# ATmega1284RFR2 device description
Architecture: AVR8; Family: megaAVR
Registers are 8-bit, access not given, no defined reset value unless marked. A register's access mark holds for its fields unless they carry their own. Offsets are from the block's base; [hi:lo] are bit positions.

## SYMCNT — MAC Symbol Counter
Instances: SYMCNT 0x00
0xD7 SCRSTRLL — Symbol Counter Received Frame Timestamp Register LL-Byte
0xD8 SCRSTRLH — Symbol Counter Received Frame Timestamp Register LH-Byte
0xD9 SCRSTRHL — Symbol Counter Received Frame Timestamp Register HL-Byte
0xDA SCRSTRHH — Symbol Counter Received Frame Timestamp Register HH-Byte
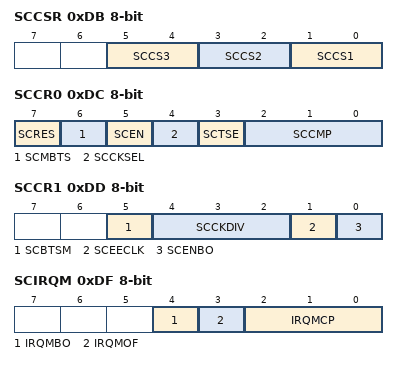
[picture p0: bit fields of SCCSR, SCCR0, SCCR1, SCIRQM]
0xDB SCCSR — Symbol Counter Compare Source Register
  [5:4] SCCS3 — Symbol Counter Compare Source select register for Compare Unit 3
    0=Compare Unit 3 Relative Compare Source = Beacon Timestamp Register; 1=Compare Unit 3 Relative Compare Source = Transmit Frame Timestamp Register; 2=Compare Unit 3 Relative Compare Source = Received Frame Timestamp Register
  [3:2] SCCS2 — Symbol Counter Compare Source select register for Compare Unit 2
    0=Compare Unit 2 Relative Compare Source = Beacon Timestamp Register; 1=Compare Unit 2 Relative Compare Source = Transmit Frame Timestamp Register; 2=Compare Unit 2 Relative Compare Source = Received Frame Timestamp Register
  [1:0] SCCS1 — Symbol Counter Compare Source select register for Compare Units
    0=Compare Unit 1 Relative Compare Source = Beacon Timestamp Register; 1=Compare Unit 1 Relative Compare Source = Transmit Frame Timestamp Register; 2=Compare Unit 1 Relative Compare Source = Received Frame Timestamp Register
0xDC SCCR0 — Symbol Counter Control Register 0
  [7] SCRES — Symbol Counter Synchronization
  [6] SCMBTS — Manual Beacon Timestamp
  [5] SCEN — Symbol Counter enable
  [4] SCCKSEL — Symbol Counter Clock Source select
  [3] SCTSE — Symbol Counter Automatic Timestamping enable
  [2:0] SCCMP (bit 1 of the value upward) — Symbol Counter Compare Unit 3 Mode select
0xDD SCCR1 — Symbol Counter Control Register 1
  [5] SCBTSM — Symbol Counter Beacon Timestamp Mask Register
  [4:2] SCCKDIV — Clock divider for synchronous clock source (16MHz Transceiver Clock)
    0=Transceiver Clock divided by 256, (62.5kHz); 1=Transceiver Clock divided by 128, (125kHz); 2=Transceiver Clock divided by 64, (250kHz); 3=Transceiver Clock divided by 32, (500kHz); 4=Transceiver Clock divided by 16, (1MHz); 5=Transceiver Clock divided by 8, (2MHz); 6=Transceiver Clock divided by 4, (4MHz)
  [1] SCEECLK — Enable External Clock Source on PG2
  [0] SCENBO — Backoff Slot Counter enable
0xDE SCSR — Symbol Counter Status Register
  [0] SCBSY — Symbol Counter busy
0xDF SCIRQM — Symbol Counter Interrupt Mask Register
  [4] IRQMBO — Backoff Slot Counter IRQ enable
  [3] IRQMOF — Symbol Counter Overflow IRQ enable
  [2:0] IRQMCP (bit 1 of the value upward) — Symbol Counter Compare Match 3 IRQ enable
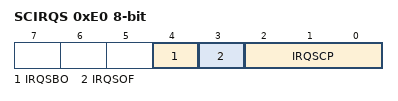
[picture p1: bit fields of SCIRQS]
0xE0 SCIRQS — Symbol Counter Interrupt Status Register
  [4] IRQSBO — Backoff Slot Counter IRQ
  [3] IRQSOF — Symbol Counter Overflow IRQ
  [2:0] IRQSCP (bit 1 of the value upward) — Compare Unit 3 Compare Match IRQ
0xE1 SCCNTLL — Symbol Counter Register LL-Byte
0xE2 SCCNTLH — Symbol Counter Register LH-Byte
0xE3 SCCNTHL — Symbol Counter Register HL-Byte
0xE4 SCCNTHH — Symbol Counter Register HH-Byte
0xE5 SCBTSRLL — Symbol Counter Beacon Timestamp Register LL-Byte
0xE6 SCBTSRLH — Symbol Counter Beacon Timestamp Register LH-Byte
0xE7 SCBTSRHL — Symbol Counter Beacon Timestamp Register HL-Byte
0xE8 SCBTSRHH — Symbol Counter Beacon Timestamp Register HH-Byte
0xE9 SCTSRLL — Symbol Counter Frame Timestamp Register LL-Byte
0xEA SCTSRLH — Symbol Counter Frame Timestamp Register LH-Byte
0xEB SCTSRHL — Symbol Counter Frame Timestamp Register HL-Byte
0xEC SCTSRHH — Symbol Counter Frame Timestamp Register HH-Byte
0xED SCOCR3LL — Symbol Counter Output Compare Register 3 LL-Byte
0xEE SCOCR3LH — Symbol Counter Output Compare Register 3 LH-Byte
0xEF SCOCR3HL — Symbol Counter Output Compare Register 3 HL-Byte
0xF0 SCOCR3HH — Symbol Counter Output Compare Register 3 HH-Byte
0xF1 SCOCR2LL — Symbol Counter Output Compare Register 2 LL-Byte
0xF2 SCOCR2LH — Symbol Counter Output Compare Register 2 LH-Byte
0xF3 SCOCR2HL — Symbol Counter Output Compare Register 2 HL-Byte
0xF4 SCOCR2HH — Symbol Counter Output Compare Register 2 HH-Byte
0xF5 SCOCR1LL — Symbol Counter Output Compare Register 1 LL-Byte
0xF6 SCOCR1LH — Symbol Counter Output Compare Register 1 LH-Byte
0xF7 SCOCR1HL — Symbol Counter Output Compare Register 1 HL-Byte
0xF8 SCOCR1HH — Symbol Counter Output Compare Register 1 HH-Byte
0xF9 SCTSTRLL — Symbol Counter Transmit Frame Timestamp Register LL-Byte
0xFA SCTSTRLH — Symbol Counter Transmit Frame Timestamp Register LH-Byte
0xFB SCTSTRHL — Symbol Counter Transmit Frame Timestamp Register HL-Byte
0xFC SCTSTRHH — Symbol Counter Transmit Frame Timestamp Register HH-Byte
